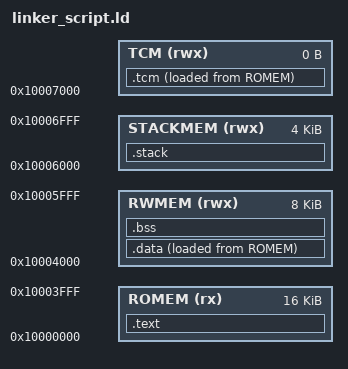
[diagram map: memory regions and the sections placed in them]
/******************************************************************************
 *
 * linker_script.ld - Linker script for applications using startup_gnu.c
 *
 *****************************************************************************/
ENTRY(Reset_Handler)

MEMORY
{
    ROMEM (rx) : ORIGIN = 0x10000000, LENGTH = 16384
    RWMEM (rwx) : ORIGIN = 0x10004000, LENGTH = 8192
    TCM (rwx) : ORIGIN = 0x10007000, LENGTH = 0
    STACKMEM (rwx) : ORIGIN = 0x10006000, LENGTH = 4096
}

SECTIONS
{
    .text :
    {
        . = ALIGN(4);
        KEEP(*(.isr_vector))
        KEEP(*(.patch))
        *(.text)
        *(.text*)
        *(.rodata)
        *(.rodata*)
        . = ALIGN(4);
        _etext = .;
    } > ROMEM

    .data :
    {
        . = ALIGN(4);
        _sdata = .;
        *(.data)
        *(.data*)
        . = ALIGN(4);
        _edata = .;
    } > RWMEM AT>ROMEM

    /* used by startup to initialize data */
    _init_data = LOADADDR(.data);

    .tcm :
    {
        . = ALIGN(4);
        _stcm = .;
        *(.tcm)
        *(.tcm*)
        . = ALIGN(4);
        _etcm = .;
    } > TCM AT>ROMEM

    /* used by startup to initialize tcm */
    _init_tcm = LOADADDR(.tcm);

    /* User stack section initialized by startup code. */
    .stack (NOLOAD):
    {
        . = ALIGN(8);
        *(.stack)
        *(.stack*)
        . = ALIGN(8);
    } > STACKMEM

    .bss :
    {
        . = ALIGN(4);
        _sbss = .;
        *(.bss)
        *(.bss*)
        *(COMMON)
        . = ALIGN(4);
        _ebss = .;
    } > RWMEM

    .ARM.attributes 0 : { *(.ARM.attributes) }
}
